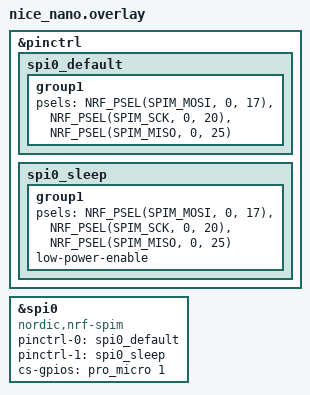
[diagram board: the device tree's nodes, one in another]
/*
 * Copyright (c) 2024 The ZMK Contributors
 * SPDX-License-Identifier: MIT
 */

/* 1. PINCTRL DEFINITIONS
 * Required by ZMK Main/Zephyr 3.5+ to define pin functions
 */
&pinctrl {
    /* Configuration for Nice!View SPI on OLED pins D2 (P0.17) & D3 (P0.20) */
    spi0_default: spi0_default {
        group1 {
            psels = <NRF_PSEL(SPIM_MOSI, 0, 17)>, /* D2 (MOSI) */
                    <NRF_PSEL(SPIM_SCK, 0, 20)>,  /* D3 (SCK) */
                    <NRF_PSEL(SPIM_MISO, 0, 25)>; /* Unused but required by definition */
        };
    };

    spi0_sleep: spi0_sleep {
        group1 {
            psels = <NRF_PSEL(SPIM_MOSI, 0, 17)>,
                    <NRF_PSEL(SPIM_SCK, 0, 20)>,
                    <NRF_PSEL(SPIM_MISO, 0, 25)>;
            low-power-enable;
        };
    };
};

/* 2. NICE!VIEW DISPLAY CONFIGURATION
 * We define the specific label 'nice_view_spi' required by the shield.
 */
nice_view_spi: &spi0 {
    compatible = "nordic,nrf-spim";
    status = "okay";
    pinctrl-0 = <&spi0_default>;
    pinctrl-1 = <&spi0_sleep>;
    pinctrl-names = "default", "sleep";
    
    /* D1 (Pro Micro 1 / P0.06) is used for Chip Select (CS) */
    cs-gpios = <&pro_micro 1 GPIO_ACTIVE_HIGH>; 
};
